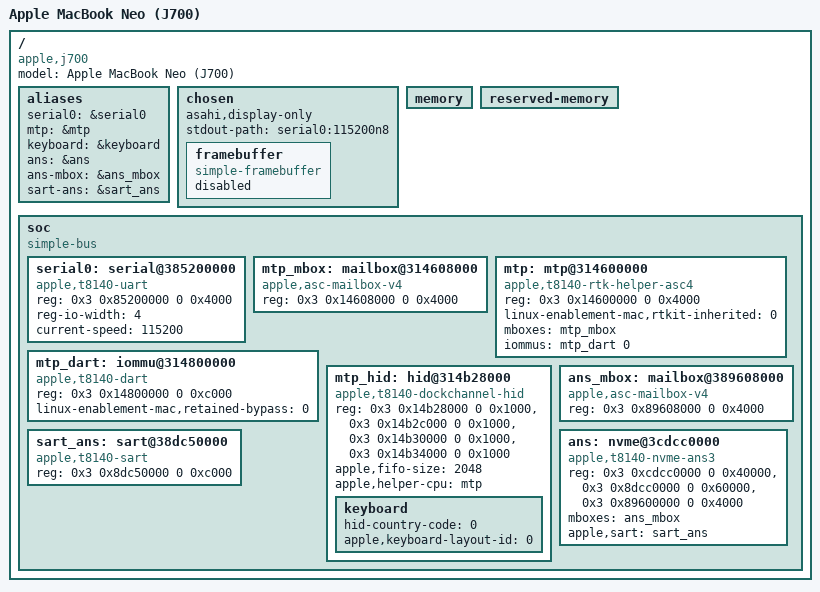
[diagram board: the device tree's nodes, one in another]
// SPDX-License-Identifier: GPL-2.0+ OR MIT
/* Console-only J700 tree. m1n1 fills in memory and inherited framebuffer. */
/dts-v1/;

/ {
	compatible = "apple,j700", "apple,t8140", "apple,arm-platform";
	model = "Apple MacBook Neo (J700)";
	#address-cells = <2>;
	#size-cells = <2>;

	aliases {
		serial0 = &serial0;
		mtp = &mtp;
		keyboard = &keyboard;
		ans = &ans;
		ans-mbox = &ans_mbox;
		sart-ans = &sart_ans;
	};

	chosen {
		#address-cells = <2>;
		#size-cells = <2>;
		ranges;
		asahi,display-only;
		stdout-path = "serial0:115200n8";
		framebuffer {
			compatible = "simple-framebuffer";
			status = "disabled";
		};
	};

	memory {
		device_type = "memory";
	};

	reserved-memory {
		#address-cells = <2>;
		#size-cells = <2>;
		ranges;
	};

	soc {
		compatible = "simple-bus";
		#address-cells = <2>;
		#size-cells = <2>;
		ranges;
		bootph-all;

		serial0: serial@385200000 {
			compatible = "apple,t8140-uart";
			reg = <0x3 0x85200000 0 0x4000>;
			reg-io-width = <4>;
			current-speed = <115200>;
			bootph-all;
		};

		/* Polled ASC mailbox; no unverified interrupt bindings. */
		mtp_mbox: mailbox@314608000 {
			compatible = "apple,asc-mailbox-v4";
			reg = <0x3 0x14608000 0 0x4000>;
			#mbox-cells = <0>;
		};

		mtp: mtp@314600000 {
			compatible = "apple,t8140-rtk-helper-asc4",
				     "apple,rtk-helper-asc4";
			reg = <0x3 0x14600000 0 0x4000>;
			reg-names = "asc";
			linux-enablement-mac,rtkit-inherited = <0>;
			mboxes = <&mtp_mbox>;
			iommus = <&mtp_dart 0>;
		};

		mtp_dart: iommu@314800000 {
			compatible = "apple,t8140-dart", "apple,t8110-dart";
			reg = <0x3 0x14800000 0 0xc000>;
			#iommu-cells = <1>;
			linux-enablement-mac,retained-bypass = <0>;
		};

		mtp_hid: hid@314b28000 {
			compatible = "apple,t8140-dockchannel-hid", "apple,dockchannel-hid";
			reg = <0x3 0x14b28000 0 0x1000>,
			      <0x3 0x14b2c000 0 0x1000>,
			      <0x3 0x14b30000 0 0x1000>,
			      <0x3 0x14b34000 0 0x1000>;
			reg-names = "rmt-config", "rmt-data", "config", "data";
			apple,fifo-size = <2048>;
			apple,helper-cpu = <&mtp>;
			keyboard: keyboard {
				hid-country-code = <0>;
				apple,keyboard-layout-id = <0>;
			};
		};

		/* Powered by iBoot; m1n1 refreshes these ranges from the live ADT. */
		ans_mbox: mailbox@389608000 {
			compatible = "apple,asc-mailbox-v4";
			reg = <0x3 0x89608000 0 0x4000>;
			#mbox-cells = <0>;
		};

		sart_ans: sart@38dc50000 {
			compatible = "apple,t8140-sart";
			reg = <0x3 0x8dc50000 0 0xc000>;
		};

		ans: nvme@3cdcc0000 {
			compatible = "apple,t8140-nvme-ans3";
			reg = <0x3 0xcdcc0000 0 0x40000>,
			      <0x3 0x8dcc0000 0 0x60000>,
			      <0x3 0x89600000 0 0x4000>;
			reg-names = "nvme", "nvmmu", "ans";
			mboxes = <&ans_mbox>;
			apple,sart = <&sart_ans>;
		};
	};
};
